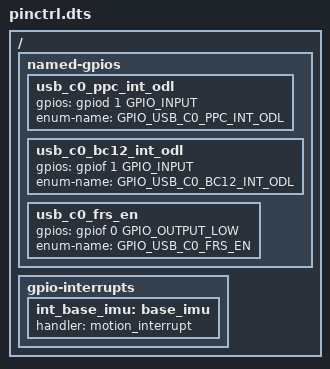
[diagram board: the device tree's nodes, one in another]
/* Copyright 2022 The ChromiumOS Authors
 * Use of this source code is governed by a BSD-style license that can be
 * found in the LICENSE file.
 */

/* remove pinctrl to avoid pull in too many unwanted dependency */
/delete-node/ &pinctrl;

/delete-node/ &{/hibernate-wake-pins};

/ {
	named-gpios {
		/delete-node/ usb_c0_ppc_bc12_int_odl;

		usb_c0_ppc_int_odl: usb_c0_ppc_int_odl {
			gpios = <&gpiod 1 GPIO_INPUT>;
			enum-name = "GPIO_USB_C0_PPC_INT_ODL";
		};

		usb_c0_bc12_int_odl: usb_c0_bc12_int_odl {
			gpios = <&gpiof 1 GPIO_INPUT>;
			enum-name = "GPIO_USB_C0_BC12_INT_ODL";
		};

		/delete-node/ usb_c0_ppc_frsinfo;

		usb_c0_frs_en: usb_c0_frs_en {
			gpios = <&gpiof 0 GPIO_OUTPUT_LOW>;
			enum-name = "GPIO_USB_C0_FRS_EN";
		};
	};

	gpio-interrupts {
		int_base_imu: base_imu {
			handler = "motion_interrupt";
		};

		/delete-node/ usb_c0_ppc_bc12;
	};
};
